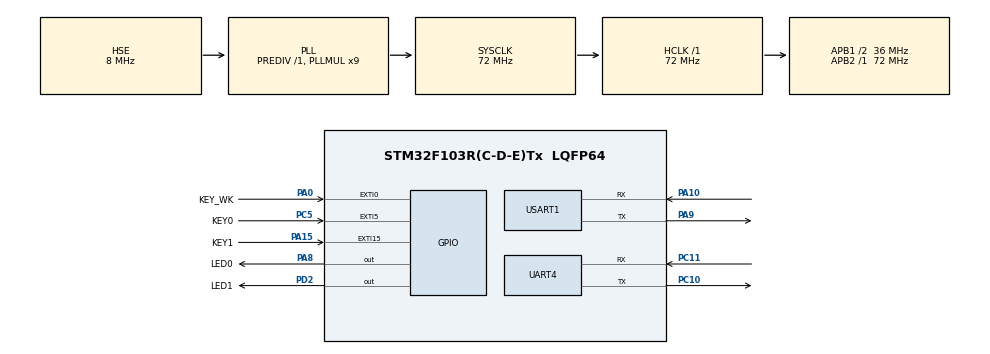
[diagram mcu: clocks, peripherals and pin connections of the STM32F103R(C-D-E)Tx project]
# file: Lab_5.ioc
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Mcu.Family=STM32F1
Mcu.Name=STM32F103R(C-D-E)Tx
Mcu.Package=LQFP64
NVIC.PriorityGroup=NVIC_PRIORITYGROUP_4
NVIC.TIM3_IRQn=true\:0\:0\:false\:false\:true\:true\:true
NVIC.UART4_IRQn=true\:0\:0\:false\:false\:true\:true\:true
NVIC.USART1_IRQn=true\:0\:0\:false\:false\:true\:true\:true
PA0-WKUP.GPIO_Label=KEY_WK
PA0-WKUP.GPIO_PuPd=GPIO_PULLDOWN
PA0-WKUP.Signal=GPXTI0
PA10.Mode=Asynchronous
PA10.Signal=USART1_RX
PA15.GPIO_Label=KEY1
PA15.GPIO_PuPd=GPIO_PULLUP
PA15.Signal=GPXTI15
PA8.GPIO_Label=LED0
PA8.Signal=GPIO_Output
PA9.Mode=Asynchronous
PA9.Signal=USART1_TX
PC10.Mode=Asynchronous
PC10.Signal=UART4_TX
PC11.Mode=Asynchronous
PC11.Signal=UART4_RX
PC14-OSC32_IN.Mode=LSE-External-Oscillator
PC14-OSC32_IN.Signal=RCC_OSC32_IN
PC15-OSC32_OUT.Mode=LSE-External-Oscillator
PC15-OSC32_OUT.Signal=RCC_OSC32_OUT
PC5.GPIO_Label=KEY0
PC5.GPIO_PuPd=GPIO_PULLUP
PC5.Signal=GPXTI5
PD0-OSC_IN.Mode=HSE-External-Oscillator
PD0-OSC_IN.Signal=RCC_OSC_IN
PD1-OSC_OUT.Mode=HSE-External-Oscillator
PD1-OSC_OUT.Signal=RCC_OSC_OUT
PD2.GPIO_Label=LED1
PD2.Signal=GPIO_Output
ProjectManager.HeapSize=0x200
ProjectManager.StackSize=0x400
ProjectManager.TargetToolchain=STM32CubeIDE
RCC.AHBFreq_Value=72000000
RCC.APB1CLKDivider=RCC_HCLK_DIV2
RCC.APB1Freq_Value=36000000
RCC.APB1TimFreq_Value=72000000
RCC.APB2Freq_Value=72000000
RCC.APB2TimFreq_Value=72000000
RCC.HCLKFreq_Value=72000000
RCC.PLLMUL=RCC_PLL_MUL9
RCC.PLLSourceVirtual=RCC_PLLSOURCE_HSE
RCC.SYSCLKFreq_VALUE=72000000
RCC.SYSCLKSource=RCC_SYSCLKSOURCE_PLLCLK
RCC.USBFreq_Value=72000000
TIM3.Period=9999
TIM3.Prescaler=7199
UART4.VirtualMode=Asynchronous
USART1.VirtualMode=VM_ASYNC
VP_SYS_VS_ND.Mode=No_Debug
VP_TIM3_VS_ClockSourceINT.Mode=Internal
board=custom

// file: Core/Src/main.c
/* USER CODE BEGIN Header */
/**
  ******************************************************************************
  * @file           : main.c
  * @brief          : Main program body
  ******************************************************************************
  * @attention
  *
  * <h2><center>&copy; Copyright (c) 2020 STMicroelectronics.
  * All rights reserved.</center></h2>
  *
  * This software component is licensed by ST under BSD 3-Clause license,
  * the "License"; You may not use this file except in compliance with the
  * License. You may obtain a copy of the License at:
  *                        opensource.org/licenses/BSD-3-Clause
  *
  ******************************************************************************
  */
/* USER CODE END Header */

#include "main.h"

TIM_HandleTypeDef htim3;

UART_HandleTypeDef huart4;
UART_HandleTypeDef huart1;

void SystemClock_Config(void);
static void MX_GPIO_Init(void);
static void MX_TIM3_Init(void);
static void MX_UART4_Init(void);
static void MX_USART1_UART_Init(void);

int main(void)
{

  /* MCU Configuration--------------------------------------------------------*/

  /* Reset of all peripherals, Initializes the Flash interface and the Systick. */
  HAL_Init();

  /* Configure the system clock */
  SystemClock_Config();

  /* Initialize all configured peripherals */
  MX_GPIO_Init();
  MX_TIM3_Init();
  MX_UART4_Init();
  MX_USART1_UART_Init();
  /* USER CODE BEGIN 2 */
  HAL_TIM_Base_Start_IT(&htim3); //add by yt
  /* USER CODE END 2 */

  /* Infinite loop */
  while (1)
  {
//	TIM3_IRQHandler();
//	HAL_GPIO_TogglePin(LED0_GPIO_Port, LED0_Pin);
	 // debugPrint(&huart1, "11810818");
  }
}

void SystemClock_Config(void)
{
  RCC_OscInitTypeDef RCC_OscInitStruct = {0};
  RCC_ClkInitTypeDef RCC_ClkInitStruct = {0};

  /** Initializes the CPU, AHB and APB busses clocks
  */
  RCC_OscInitStruct.OscillatorType = RCC_OSCILLATORTYPE_HSE;
  RCC_OscInitStruct.HSEState = RCC_HSE_ON;
  RCC_OscInitStruct.HSEPredivValue = RCC_HSE_PREDIV_DIV1;
  RCC_OscInitStruct.HSIState = RCC_HSI_ON;
  RCC_OscInitStruct.PLL.PLLState = RCC_PLL_ON;
  RCC_OscInitStruct.PLL.PLLSource = RCC_PLLSOURCE_HSE;
  RCC_OscInitStruct.PLL.PLLMUL = RCC_PLL_MUL9;
  if (HAL_RCC_OscConfig(&RCC_OscInitStruct) != HAL_OK)
  {
    Error_Handler();
  }
  /** Initializes the CPU, AHB and APB busses clocks
  */
  RCC_ClkInitStruct.ClockType = RCC_CLOCKTYPE_HCLK|RCC_CLOCKTYPE_SYSCLK
                              |RCC_CLOCKTYPE_PCLK1|RCC_CLOCKTYPE_PCLK2;
  RCC_ClkInitStruct.SYSCLKSource = RCC_SYSCLKSOURCE_PLLCLK;
  RCC_ClkInitStruct.AHBCLKDivider = RCC_SYSCLK_DIV1;
  RCC_ClkInitStruct.APB1CLKDivider = RCC_HCLK_DIV2;
  RCC_ClkInitStruct.APB2CLKDivider = RCC_HCLK_DIV1;

  if (HAL_RCC_ClockConfig(&RCC_ClkInitStruct, FLASH_LATENCY_2) != HAL_OK)
  {
    Error_Handler();
  }
}

static void MX_TIM3_Init(void)
{

  TIM_ClockConfigTypeDef sClockSourceConfig = {0};
  TIM_MasterConfigTypeDef sMasterConfig = {0};

  htim3.Instance = TIM3;
  htim3.Init.Prescaler = 7199;
  htim3.Init.CounterMode = TIM_COUNTERMODE_UP;
  htim3.Init.Period = 9999;
  htim3.Init.ClockDivision = TIM_CLOCKDIVISION_DIV1;
  htim3.Init.AutoReloadPreload = TIM_AUTORELOAD_PRELOAD_DISABLE;
  if (HAL_TIM_Base_Init(&htim3) != HAL_OK)
  {
    Error_Handler();
  }
  sClockSourceConfig.ClockSource = TIM_CLOCKSOURCE_INTERNAL;
  if (HAL_TIM_ConfigClockSource(&htim3, &sClockSourceConfig) != HAL_OK)
  {
    Error_Handler();
  }
  sMasterConfig.MasterOutputTrigger = TIM_TRGO_RESET;
  sMasterConfig.MasterSlaveMode = TIM_MASTERSLAVEMODE_DISABLE;
  if (HAL_TIMEx_MasterConfigSynchronization(&htim3, &sMasterConfig) != HAL_OK)
  {
    Error_Handler();
  }

}

static void MX_UART4_Init(void)
{

  huart4.Instance = UART4;
  huart4.Init.BaudRate = 115200;
  huart4.Init.WordLength = UART_WORDLENGTH_8B;
  huart4.Init.StopBits = UART_STOPBITS_1;
  huart4.Init.Parity = UART_PARITY_NONE;
  huart4.Init.Mode = UART_MODE_TX_RX;
  huart4.Init.HwFlowCtl = UART_HWCONTROL_NONE;
  huart4.Init.OverSampling = UART_OVERSAMPLING_16;
  if (HAL_UART_Init(&huart4) != HAL_OK)
  {
    Error_Handler();
  }

}

static void MX_USART1_UART_Init(void)
{

  huart1.Instance = USART1;
  huart1.Init.BaudRate = 115200;
  huart1.Init.WordLength = UART_WORDLENGTH_8B;
  huart1.Init.StopBits = UART_STOPBITS_1;
  huart1.Init.Parity = UART_PARITY_NONE;
  huart1.Init.Mode = UART_MODE_TX_RX;
  huart1.Init.HwFlowCtl = UART_HWCONTROL_NONE;
  huart1.Init.OverSampling = UART_OVERSAMPLING_16;
  if (HAL_UART_Init(&huart1) != HAL_OK)
  {
    Error_Handler();
  }

}

static void MX_GPIO_Init(void)
{
  GPIO_InitTypeDef GPIO_InitStruct = {0};

  /* GPIO Ports Clock Enable */
  __HAL_RCC_GPIOC_CLK_ENABLE();
  __HAL_RCC_GPIOD_CLK_ENABLE();
  __HAL_RCC_GPIOA_CLK_ENABLE();

  /*Configure GPIO pin Output Level */
  HAL_GPIO_WritePin(LED0_GPIO_Port, LED0_Pin, GPIO_PIN_RESET);

  /*Configure GPIO pin Output Level */
  HAL_GPIO_WritePin(LED1_GPIO_Port, LED1_Pin, GPIO_PIN_RESET);

  /*Configure GPIO pin : KEY_WK_Pin */
  GPIO_InitStruct.Pin = KEY_WK_Pin;
  GPIO_InitStruct.Mode = GPIO_MODE_IT_RISING;
  GPIO_InitStruct.Pull = GPIO_PULLDOWN;
  HAL_GPIO_Init(KEY_WK_GPIO_Port, &GPIO_InitStruct);

  /*Configure GPIO pin : KEY0_Pin */
  GPIO_InitStruct.Pin = KEY0_Pin;
  GPIO_InitStruct.Mode = GPIO_MODE_IT_RISING;
  GPIO_InitStruct.Pull = GPIO_PULLUP;
  HAL_GPIO_Init(KEY0_GPIO_Port, &GPIO_InitStruct);

  /*Configure GPIO pin : LED0_Pin */
  GPIO_InitStruct.Pin = LED0_Pin;
  GPIO_InitStruct.Mode = GPIO_MODE_OUTPUT_PP;
  GPIO_InitStruct.Pull = GPIO_NOPULL;
  GPIO_InitStruct.Speed = GPIO_SPEED_FREQ_LOW;
  HAL_GPIO_Init(LED0_GPIO_Port, &GPIO_InitStruct);

  /*Configure GPIO pin : KEY1_Pin */
  GPIO_InitStruct.Pin = KEY1_Pin;
  GPIO_InitStruct.Mode = GPIO_MODE_IT_RISING;
  GPIO_InitStruct.Pull = GPIO_PULLUP;
  HAL_GPIO_Init(KEY1_GPIO_Port, &GPIO_InitStruct);

  /*Configure GPIO pin : LED1_Pin */
  GPIO_InitStruct.Pin = LED1_Pin;
  GPIO_InitStruct.Mode = GPIO_MODE_OUTPUT_PP;
  GPIO_InitStruct.Pull = GPIO_NOPULL;
  GPIO_InitStruct.Speed = GPIO_SPEED_FREQ_LOW;
  HAL_GPIO_Init(LED1_GPIO_Port, &GPIO_InitStruct);

}

/* USER CODE BEGIN 4 */

// add=============================================================
void debugPrint(UART_HandleTypeDef *huart, char _out[]){
	HAL_UART_Transmit(huart, (uint8_t *) _out, strlen(_out), 10);
}

void debugPrintln(UART_HandleTypeDef *huart, char _out[]){
	 HAL_UART_Transmit(huart, (uint8_t *) _out, strlen(_out), 10);
	 char newline[2] = "\r\n";
	 HAL_UART_Transmit(huart, (uint8_t *) newline, 2, 10);
}
// ================================================================

/* USER CODE END 4 */

void Error_Handler(void)
{
}

/************************ (C) COPYRIGHT STMicroelectronics *****END OF FILE****/
